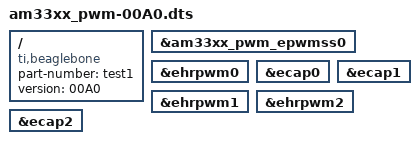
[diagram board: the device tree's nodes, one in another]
/*
 * Copyright (C) 2013 CircuitCo
 * Copyright (C) 2013 Texas Instruments
 *
 * This program is free software; you can redistribute it and/or modify
 * it under the terms of the GNU General Public License version 2 as
 * published by the Free Software Foundation.
 */
/dts-v1/;
/plugin/;

/ {
	compatible = "ti,beaglebone";

	/* identification */
	part-number = "test1";
	version = "00A0";

	fragment@0 {
		target = <&am33xx_pwm_epwmss0>;
		__overlay__ {
			status = "okay";
		};
	};

	fragment@1 {
		target = <&ehrpwm0>;
		__overlay__ {
			status = "okay";
		};
	};

	fragment@2 {
		target = <&ecap0>;
		__overlay__ {
			status = "okay";
		};
	};

	fragment@3 {
		target = <&ehrpwm1>;
		__overlay__ {
			status = "okay";
		};
	};

	fragment@4 {
		target = <&ecap1>;
		__overlay__ {
			status = "okay";
		};
	};

	fragment@5 {
		target = <&ehrpwm2>;
		__overlay__ {
			status = "okay";
		};
	};

	fragment@6 {
		target = <&ecap2>;
		__overlay__ {
			status = "okay";
		};
	};
};
